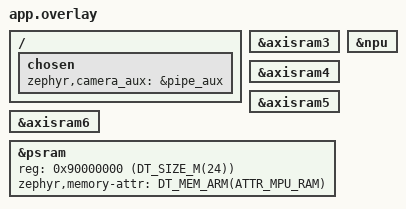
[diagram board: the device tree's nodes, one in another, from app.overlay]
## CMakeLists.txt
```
##############################################################################
# @file    CMakeLists.txt
# @author  GPM Application Team
#
##############################################################################
# @attention
#
# Copyright (c) 2025 STMicroelectronics.
# All rights reserved.
#
# This software is licensed under terms that can be found in the LICENSE file
# in the root directory of this software component.
# If no LICENSE file comes with this software, it is provided AS-IS.
#
##############################################################################

cmake_minimum_required(VERSION 3.20.0)

set(BOARD stm32n6570_dk)
set(SHIELD st_b_cams_imx_mb1854)

find_package(Zephyr REQUIRED HINTS $ENV{ZEPHYR_BASE})

project(app LANGUAGES C)

target_include_directories(app PRIVATE inc Model)
target_sources(app PRIVATE src/main.c src/model.c Model/network.c Model/stai_network.c src/zephyr_logo.c)

# lib_vision_models_pp
target_include_directories(app PRIVATE ../Lib/lib_vision_models_pp/lib_vision_models_pp/Inc
                           ../Lib/lib_vision_models_pp/Drivers/CMSIS/DSP/Include)

target_sources(app PRIVATE ../Lib/lib_vision_models_pp/lib_vision_models_pp/Src/vision_models_pp.c
                           ../Lib/lib_vision_models_pp/lib_vision_models_pp/Src/vision_models_pp_maxi_if32.c
                           ../Lib/lib_vision_models_pp/lib_vision_models_pp/Src/vision_models_pp_maxi_is8.c
                           ../Lib/lib_vision_models_pp/lib_vision_models_pp/Src/vision_models_pp_maxi_iu8.c
                           ../Lib/lib_vision_models_pp/lib_vision_models_pp/Src/od_pp_yolov2.c
                           ../Lib/lib_vision_models_pp/lib_vision_models_pp/Src/od_pp_yolov5.c
                           ../Lib/lib_vision_models_pp/lib_vision_models_pp/Src/od_pp_yolov8.c
                           ../Lib/lib_vision_models_pp/lib_vision_models_pp/Src/od_pp_st_yolox.c)

# AI_Runtime
target_compile_definitions(app PRIVATE LL_ATON_PLATFORM=LL_ATON_PLAT_STM32N6
                           LL_ATON_OSAL=LL_ATON_OSAL_ZEPHYR
                           LL_ATON_RT_MODE=LL_ATON_RT_ASYNC
                           LL_ATON_SW_FALLBACK
                           LL_ATON_DBG_BUFFER_INFO_EXCLUDED=1
                           APP_HAS_PARALLEL_NETWORKS=0)

target_include_directories(app PRIVATE ../Lib/AI_Runtime/Inc
                           ../Lib/AI_Runtime/Npu/ll_aton
                           ../Lib/AI_Runtime/Npu/Devices/STM32N6xx)

target_sources(app PRIVATE ../Lib/AI_Runtime/Npu/ll_aton/ll_aton.c
               ../Lib/AI_Runtime/Npu/ll_aton/ll_aton_osal_zephyr.c
               ../Lib/AI_Runtime/Npu/ll_aton/ll_aton_debug.c
               ../Lib/AI_Runtime/Npu/ll_aton/ll_aton_lib.c
               ../Lib/AI_Runtime/Npu/ll_aton/ll_aton_lib_sw_operators.c
               ../Lib/AI_Runtime/Npu/ll_aton/ll_aton_rt_main.c
               ../Lib/AI_Runtime/Npu/ll_aton/ll_aton_runtime.c
               ../Lib/AI_Runtime/Npu/ll_aton/ll_aton_cipher.c
               ../Lib/AI_Runtime/Npu/ll_aton/ll_aton_stai_internal.c
               ../Lib/AI_Runtime/Npu/ll_aton/ll_aton_util.c
               ../Lib/AI_Runtime/Npu/ll_aton/ll_sw_float.c
               ../Lib/AI_Runtime/Npu/ll_aton/ll_sw_integer.c
               ../Lib/AI_Runtime/Npu/ll_aton/ecloader.c
               ../Lib/AI_Runtime/Npu/Devices/STM32N6xx/npu_cache.c
               ../Lib/AI_Runtime/Npu/Devices/STM32N6xx/mcu_cache.c)

target_link_directories(app PUBLIC ../Lib/AI_Runtime/Lib/GCC/ARMCortexM55)

target_link_libraries(app PRIVATE :NetworkRuntime1100_CM55_GCC.a)
```

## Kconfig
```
##############################################################################
# @file    Kconfig
# @author  GPM Application Team
#
##############################################################################
# @attention
#
# Copyright (c) 2025 STMicroelectronics.
# All rights reserved.
#
# This software is licensed under terms that can be found in the LICENSE file
# in the root directory of this software component.
# If no LICENSE file comes with this software, it is provided AS-IS.
#
##############################################################################

mainmenu "Zephyr people detect"

menu "Application options"
config MY_APP
	bool "Enable app"
	default y
	select USE_STM32_HAL_RAMCFG
	select USE_STM32_HAL_CACHEAXI
	select FPU
	select CMSIS_DSP
	help
		enable application

endmenu

source "Kconfig.zephyr"
```

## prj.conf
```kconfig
# Copyright (c) 2025 STMicroelectronics
# All rights reserved.
#
# This software is licensed under terms that can be found in the LICENSE file
# in the root directory of this software component.
# If no LICENSE file comes with this software, it is provided AS-IS.

CONFIG_MY_APP=y
CONFIG_MAIN_STACK_SIZE=8192
# CONFIG_XIP is not set
CONFIG_USE_STM32_MW_ISP=y
CONFIG_DYNAMIC_INTERRUPTS=y
CONFIG_FLASH=y
CONFIG_HW_STACK_PROTECTION=y
CONFIG_LOG=y
CONFIG_ASSERT=y
CONFIG_LV_USE_CANVAS=y
CONFIG_LV_USE_THEME_DEFAULT=y
CONFIG_LVGL=y
CONFIG_LV_Z_MEM_POOL_SIZE=8192
# CONFIG_THREAD_MONITOR is not set
# CONFIG_THREAD_NAME is not set
CONFIG_DISPLAY=y
CONFIG_FLASH_STM32_NOR_MEMMAP=y
CONFIG_VIDEO=y
CONFIG_VIDEO_BUFFER_POOL_NUM_MAX=4
CONFIG_VIDEO_BUFFER_POOL_HEAP_SIZE=2575000
CONFIG_VIDEO_STM32_DCMIPP_SENSOR_WIDTH=2592
CONFIG_VIDEO_STM32_DCMIPP_SENSOR_HEIGHT=1944
CONFIG_VIDEO_STM32_DCMIPP_SENSOR_PIXEL_FORMAT="pRAA"
CONFIG_CPU_LOAD=y
# To be sure LOGGER can still ouput message move this one priority level above main thread
CONFIG_LOG_PROCESS_THREAD_CUSTOM_PRIORITY=y
CONFIG_LOG_PROCESS_THREAD_PRIORITY=13
CONFIG_LV_FONT_UNSCII_16=y
CONFIG_LV_Z_MEM_POOL_SIZE=12288
```

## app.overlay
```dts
/*
 * Copyright (c) 2025 STMicroelectronics.
 * All rights reserved.
 *
 * This software is licensed under terms that can be found in the LICENSE file
 * in the root directory of this software component.
 * If no LICENSE file comes with this software, it is provided AS-IS.
 */

/ {
	chosen {
		zephyr,camera_aux = &pipe_aux;
	};
};

// Turn on so called npu rams. They will used by NPU for model actvation buffers
&axisram3 {
	status = "okay";
};
&axisram4 {
	status = "okay";
};
&axisram5 {
	status = "okay";
};
&axisram6 {
	status = "okay";
};

// Turn on npu
&npu {
	status = "okay";
};

// Temporary patch that allows to turn on cache on psram
// Remove this when merge upstream
&psram {
	/* Let last 8 Mbytes for Model usage */
	reg = <0x90000000 (DT_SIZE_M(24))>;
	zephyr,memory-attr = <DT_MEM_ARM(ATTR_MPU_RAM)>;
};
```

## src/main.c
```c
/**
 ******************************************************************************
 * @file    main.c
 * @author  GPM Application Team
 *
 ******************************************************************************
 * @attention
 *
 * Copyright (c) 2025 STMicroelectronics.
 * All rights reserved.
 *
 * This software is licensed under terms that can be found in the LICENSE file
 * in the root directory of this software component.
 * If no LICENSE file comes with this software, it is provided AS-IS.
 *
 ******************************************************************************
 */

#include <zephyr/kernel.h>
#include <zephyr/drivers/video.h>
#include <zephyr/drivers/display.h>
#include <zephyr/sys/__assert.h>
#include <zephyr/sys/cpu_load.h>
#include <zephyr/logging/log.h>
#include <zephyr/sys/util.h>

#include <lvgl.h>

#include <stdarg.h>

#include "model.h"
#include "stai_network.h"

LOG_MODULE_REGISTER(main);

#define DISPLAY_WIDTH DT_PROP(DT_CHOSEN(zephyr_display), width)
#define DISPLAY_HEIGHT DT_PROP(DT_CHOSEN(zephyr_display), height)
#define DISPLAY_BPP 2

#define NN_WIDTH STAI_NETWORK_IN_1_WIDTH
#define NN_HEIGHT STAI_NETWORK_IN_1_HEIGHT
#define NN_BPP 3
#define NPU_BUFFER_POOL_ALIGN 32

/* Tune ui layout */
#define APP_DRAW_INF_TIME 0
#define APP_DRAW_INF_FPS 1
#define APP_DRAW_CPU_LOAD 0
#define APP_DRAW_LOGO 1

LV_IMAGE_DECLARE(zephyr_logo);

static struct k_thread nn_thread;
static K_THREAD_STACK_DEFINE(nn_thread_stack, 4096);

static int display_setup(const struct device *const display_dev)
{
	int ret;

	ret = display_set_pixel_format(display_dev, PIXEL_FORMAT_RGB_565);
	__ASSERT_NO_MSG(ret == 0);

	ret = display_blanking_off(display_dev);
	__ASSERT_NO_MSG(ret == 0);

	return 0;
}

static void print_text(lv_layer_t *layer, int x, int y, lv_text_align_t align, char *fmt, ...)
{
	lv_draw_label_dsc_t tdsc;
	char text_buffer[128];
	lv_area_t coords;
	va_list ap;

	va_start(ap, fmt);
	vsnprintf(text_buffer, sizeof(text_buffer), fmt, ap);

	/* shadow */
	lv_draw_label_dsc_init(&tdsc);
	tdsc.color = lv_color_make(16, 16, 16);
	tdsc.font = &lv_font_unscii_16;
	coords.x1 = x + 1;
	coords.y1 = y + 1;
	coords.x2 = DISPLAY_WIDTH;
	coords.y2 = DISPLAY_HEIGHT;
	tdsc.text = text_buffer;
	tdsc.text_local = 1;
	tdsc.align = align;
	lv_draw_label(layer, &tdsc, &coords);

	/* text */
	tdsc.color = lv_color_make(255, 255, 255);
	coords.x1 = x;
	coords.y1 = y;
	lv_draw_label(layer, &tdsc, &coords);
	va_end(ap);
}

static void decorate_canvas(lv_obj_t * canvas)
{
	int latest_inference_time = model_get_latest_inference_time();
	const lv_font_t *font = &lv_font_unscii_16;
	lv_draw_image_dsc_t idsc;
	lv_draw_rect_dsc_t rdsc;
	struct dbox boxes[10];
	lv_area_t coords;
	lv_layer_t layer;
	struct dbox *b;
	uint32_t ver;
	int load;
	int nb;
	int i;

	ver = sys_kernel_version_get();
	nb = model_get_boxes(boxes, ARRAY_SIZE(boxes));

	lv_canvas_init_layer(canvas, &layer);
	/* Draw banner */
	print_text(&layer, 0, 0, LV_TEXT_ALIGN_CENTER, "YoloX People Detection");
	print_text(&layer, 0, font->line_height, LV_TEXT_ALIGN_CENTER, "Powered by zephyr OS %d.%d.%d",
		   SYS_KERNEL_VER_MAJOR(ver), SYS_KERNEL_VER_MINOR(ver), SYS_KERNEL_VER_PATCHLEVEL(ver));

	/* Draw inference time */
	if (APP_DRAW_INF_TIME) {
		print_text(&layer, 0, DISPLAY_HEIGHT - font->line_height * 3, LV_TEXT_ALIGN_LEFT, "Inference %d ms",
			   latest_inference_time);
	}
	/* Draw inference fps */
	if (APP_DRAW_INF_FPS) {
		latest_inference_time = latest_inference_time ? latest_inference_time : 1;
		print_text(&layer, 0, DISPLAY_HEIGHT - font->line_height * 2, LV_TEXT_ALIGN_LEFT, "Fps       %d",
			   1000 / latest_inference_time);
	}
	/* Draw cpu load */
#ifdef CONFIG_CPU_LOAD
	if (APP_DRAW_CPU_LOAD) {
		load = cpu_load_get(1);
		print_text(&layer, 0, DISPLAY_HEIGHT - font->line_height * 1, LV_TEXT_ALIGN_LEFT, "cpu load  %d.%d%%",
			   load / 10, load % 10);
	}
#else
	(void)load;
#endif

	/* Draw logo */
	if (APP_DRAW_LOGO) {
		lv_draw_image_dsc_init(&idsc);
		idsc.src = &zephyr_logo;
		coords.x1 = DISPLAY_WIDTH - zephyr_logo.header.w - 10;
		coords.y1 = DISPLAY_HEIGHT - zephyr_logo.header.h - 10;
		coords.x2 = coords.x1 + zephyr_logo.header.w - 1;
		coords.y2 = coords.y1 + zephyr_logo.header.h - 1;
		lv_draw_image(&layer, &idsc, &coords);
	}

	/* Draw boxes */
	lv_draw_rect_dsc_init(&rdsc);
	rdsc.border_color = lv_palette_main(LV_PALETTE_GREEN);
	rdsc.border_width = 2;
	rdsc.radius = 10;
	rdsc.bg_opa = 0;
	for (i = 0; i < nb; i++) {
		b = &boxes[i];
		coords.x1 = b->x;
		coords.y1 = b->y;
		coords.x2 = b->x + b->w;
		coords.y2 = b->y + b->h;
		lv_draw_rect(&layer, &rdsc, &coords);
	}

	lv_canvas_finish_layer(canvas, &layer);
}

static int video_crop_setup(const struct device *const video_dev, uint32_t sensor_width, uint32_t sensor_height)
{
	const float ratioy = (float)sensor_height / DISPLAY_HEIGHT;
	const float ratiox = (float)sensor_width / DISPLAY_WIDTH;
	const float ratio = MIN(ratiox, ratioy);
	struct video_selection crop = {
		.type = VIDEO_BUF_TYPE_OUTPUT,
	};
	int ret;

	__ASSERT_NO_MSG(ratio >= 1);
	__ASSERT_NO_MSG(ratio < 64);

	crop.target = VIDEO_SEL_TGT_CROP;
	crop.rect.width = DISPLAY_WIDTH * ratio;
	crop.rect.height = DISPLAY_HEIGHT * ratio;
	crop.rect.left = (sensor_width - crop.rect.width + 1) /2;
	crop.rect.top = (sensor_height - crop.rect.height + 1) / 2;

	ret = video_set_selection(video_dev, &crop);
	__ASSERT_NO_MSG(ret == 0);

	return 0;
}

static int video_resize_setup(const struct device *const video_dev, uint32_t width, uint32_t height)
{
	struct video_selection comp = {
		.type = VIDEO_BUF_TYPE_OUTPUT,
	};
	int ret;

	comp.target = VIDEO_SEL_TGT_COMPOSE;
	comp.rect.left = 0;
	comp.rect.top = 0;
	comp.rect.width = width;
	comp.rect.height = height;

	ret = video_set_selection(video_dev, &comp);
	__ASSERT_NO_MSG(ret == 0);

	return 0;
}

static int video_alloc_and_queue_buffers(const struct device *const video_dev, size_t bsize, int align)
{
	struct video_buffer *buffers[2];
	int ret;
	int i;

	for (i = 0; i < ARRAY_SIZE(buffers); i++) {
		buffers[i] = video_buffer_aligned_alloc(bsize, align, K_FOREVER);
		__ASSERT_NO_MSG(buffers[i]);
		buffers[i]->type = VIDEO_BUF_TYPE_OUTPUT;
		ret = video_enqueue(video_dev, buffers[i]);
		__ASSERT_NO_MSG(ret == 0);
		LOG_INF("buffer %p(%p) queue to %s pipe", (void *)buffers[i], (void *)buffers[i]->buffer, video_dev->name);
	}

	return 0;
}

static int video_main_setup(const struct device *const video_dev, uint32_t sensor_width, uint32_t sensor_height)
{
	struct video_format fmt;
	size_t bsize;
	int ret;

	/* setup crop, compose and output */
	ret = video_crop_setup(video_dev, sensor_width, sensor_height);
	__ASSERT_NO_MSG(ret == 0);
	ret = video_resize_setup(video_dev, DISPLAY_WIDTH, DISPLAY_HEIGHT);
	__ASSERT_NO_MSG(ret == 0);
	fmt.pixelformat = VIDEO_FOURCC_FROM_STR("RGBP");
	fmt.width = DISPLAY_WIDTH;
	fmt.height = DISPLAY_HEIGHT;
	fmt.pitch = fmt.width * DISPLAY_BPP;
	ret = video_set_format(video_dev, &fmt);
	__ASSERT_NO_MSG(ret == 0);

	/* alloc buffers and queue them */
	bsize = fmt.pitch * fmt.height;
	ret = video_alloc_and_queue_buffers(video_dev, bsize, CONFIG_VIDEO_BUFFER_POOL_ALIGN);
	__ASSERT_NO_MSG(ret == 0);

	return 0;
}

static int video_aux_setup(const struct device *const video_dev, uint32_t sensor_width, uint32_t sensor_height)
{
	struct video_format fmt;
	size_t bsize;
	int ret;

	/* setup crop, compose and output */
	ret = video_crop_setup(video_dev, sensor_width, sensor_height);
	__ASSERT_NO_MSG(ret == 0);
	ret = video_resize_setup(video_dev, NN_WIDTH, NN_HEIGHT);
	__ASSERT_NO_MSG(ret == 0);
	fmt.pixelformat = VIDEO_FOURCC_FROM_STR("RGB3");
	fmt.width = NN_WIDTH;
	fmt.height = NN_HEIGHT;
	fmt.pitch = fmt.width * NN_BPP;
	ret = video_set_format(video_dev, &fmt);
	__ASSERT_NO_MSG(ret == 0);

	/* alloc buffers and queue them */
	bsize = fmt.pitch * fmt.height;
	ret = video_alloc_and_queue_buffers(video_dev, bsize, NPU_BUFFER_POOL_ALIGN);
	__ASSERT_NO_MSG(ret == 0);

	return 0;
}

static int video_setup(const struct device *const main_dev, const struct device *const aux_dev)
{
	struct video_format fmt;
	uint32_t sensor_height;
	uint32_t sensor_width;
	int ret;

	/* get default format to get sensor width / height */
	ret = video_get_format(main_dev, &fmt);
	__ASSERT_NO_MSG(ret == 0);
	sensor_height = fmt.height;
	sensor_width = fmt.width;

	ret = video_main_setup(main_dev, sensor_width, sensor_height);
	__ASSERT_NO_MSG(ret == 0);

	ret = video_aux_setup(aux_dev, sensor_width, sensor_height);
	__ASSERT_NO_MSG(ret == 0);

	return 0;
}

int main()
{
	const struct device *const camera_aux_dev = DEVICE_DT_GET(DT_CHOSEN(zephyr_camera_aux));
	const struct device *const display_dev = DEVICE_DT_GET(DT_CHOSEN(zephyr_display));
	const struct device *const video_dev = DEVICE_DT_GET(DT_CHOSEN(zephyr_camera));
	struct video_buffer *vbuf;
	lv_obj_t *canvas;
	k_tid_t nn_tid;
	int ret;

	__ASSERT_NO_MSG(device_is_ready(video_dev));
	__ASSERT_NO_MSG(device_is_ready(camera_aux_dev));
	__ASSERT_NO_MSG(device_is_ready(display_dev));

	/* move main thread priority to lowest one so we let others thread a chance to run */
	k_thread_priority_set(k_current_get(), K_LOWEST_APPLICATION_THREAD_PRIO);

	/* create thread for nn process */
	nn_tid = k_thread_create(&nn_thread, nn_thread_stack, K_THREAD_STACK_SIZEOF(nn_thread_stack), model_thread_ep,
				 (void *) camera_aux_dev, NULL, NULL, 0, 0, K_NO_WAIT);
	__ASSERT_NO_MSG(nn_tid);

	/* Configure display */
	ret = display_setup(display_dev);
	__ASSERT_NO_MSG(ret == 0);

	/* Configure video pipe */
	ret = video_setup(video_dev, camera_aux_dev);
	__ASSERT_NO_MSG(ret == 0);

	/* Start main pipe */
	LOG_INF("Starting main pipe");
	ret = video_stream_start(video_dev, VIDEO_BUF_TYPE_OUTPUT);
	__ASSERT_NO_MSG(ret == 0);

	LOG_INF("Starting aux pipe");
	ret = video_stream_start(camera_aux_dev, VIDEO_BUF_TYPE_OUTPUT);
	__ASSERT_NO_MSG(ret == 0);

	LOG_INF("STARTING");

	canvas = lv_canvas_create(lv_scr_act());
	while (1) {
		ret = video_dequeue(video_dev, &vbuf, K_FOREVER);
		__ASSERT_NO_MSG(ret == 0);

		lv_canvas_set_buffer(canvas, vbuf->buffer, DISPLAY_WIDTH, DISPLAY_HEIGHT, LV_COLOR_FORMAT_RGB565);
		decorate_canvas(canvas);
		lv_timer_handler();

		ret = video_enqueue(video_dev, vbuf);
		__ASSERT_NO_MSG(ret == 0);
	}

	return 0;
}
```

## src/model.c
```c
/**
 ******************************************************************************
 * @file    model.c
 * @author  GPM Application Team
 *
 ******************************************************************************
 * @attention
 *
 * Copyright (c) 2025 STMicroelectronics.
 * All rights reserved.
 *
 * This software is licensed under terms that can be found in the LICENSE file
 * in the root directory of this software component.
 * If no LICENSE file comes with this software, it is provided AS-IS.
 *
 ******************************************************************************
 */

#include "model.h"

#include <stdlib.h>

#include <zephyr/cache.h>
#include <zephyr/drivers/video.h>
#include <zephyr/logging/log.h>
#include <zephyr/mem_mgmt/mem_attr_heap.h>

#include "npu_cache.h"
#include "stai.h"
#include "stai_network.h"
#include "od_st_yolox_pp_if.h"

#define DISPLAY_WIDTH DT_PROP(DT_CHOSEN(zephyr_display), width)
#define DISPLAY_HEIGHT DT_PROP(DT_CHOSEN(zephyr_display), height)

/* post process conf */
 /* Tunable post process parameters */
#define AI_OD_ST_YOLOX_PP_IOU_THRESHOLD             (0.5)
#define AI_OD_ST_YOLOX_PP_CONF_THRESHOLD            (0.6)
#define AI_OD_ST_YOLOX_PP_MAX_BOXES_LIMIT           (10)
 /* Model related defines */
#define AI_OD_ST_YOLOX_PP_NB_CLASSES                (1)
#define AI_OD_ST_YOLOX_PP_L_GRID_WIDTH              (52)
#define AI_OD_ST_YOLOX_PP_L_GRID_HEIGHT             (52)
#define AI_OD_ST_YOLOX_PP_M_GRID_WIDTH              (26)
#define AI_OD_ST_YOLOX_PP_M_GRID_HEIGHT             (26)
#define AI_OD_ST_YOLOX_PP_S_GRID_WIDTH              (13)
#define AI_OD_ST_YOLOX_PP_S_GRID_HEIGHT             (13)
#define AI_OD_ST_YOLOX_PP_NB_ANCHORS                (3)
/* Anchor boxes */
static const float32_t AI_OD_ST_YOLOX_PP_L_ANCHORS[2 * AI_OD_ST_YOLOX_PP_NB_ANCHORS] = {26.000000, 26.000000, 3.640000, 13.000000, 11.960000, 36.40000};
static const float32_t AI_OD_ST_YOLOX_PP_M_ANCHORS[2 * AI_OD_ST_YOLOX_PP_NB_ANCHORS] = {13.000000, 13.000000, 1.820000,  6.500000,  5.980000, 18.20000};
static const float32_t AI_OD_ST_YOLOX_PP_S_ANCHORS[2 * AI_OD_ST_YOLOX_PP_NB_ANCHORS] = { 6.500000,  6.500000, 0.910000,  3.250000,  2.990000,  9.10000};


LOG_MODULE_REGISTER(model);

/* Model instance buffer */
static uint8_t network_ctx[STAI_NETWORK_CONTEXT_SIZE] __attribute__ ((aligned (32)));

/* Post process */
static stai_network_info *current_info;
static size_t output_order_index[3];

/* latest detections and associate mutex */
static od_pp_outBuffer_t pp_detections_buffer[AI_OD_ST_YOLOX_PP_NB_ANCHORS *
					      MAX(AI_OD_ST_YOLOX_PP_MAX_BOXES_LIMIT,
						  AI_OD_ST_YOLOX_PP_L_GRID_WIDTH * AI_OD_ST_YOLOX_PP_L_GRID_HEIGHT +
						  AI_OD_ST_YOLOX_PP_M_GRID_WIDTH * AI_OD_ST_YOLOX_PP_M_GRID_HEIGHT +
						  AI_OD_ST_YOLOX_PP_S_GRID_WIDTH * AI_OD_ST_YOLOX_PP_S_GRID_HEIGHT)];
static od_pp_outBuffer_t detections[AI_OD_ST_YOLOX_PP_MAX_BOXES_LIMIT];
static int detections_nb = -1;
static struct k_mutex boxes_lock;

static int latest_inference_time = 0;

static void Run_Inference(stai_network *network_instance)
{
	stai_return_code ret;

	do {
		ret = stai_network_run(network_instance, STAI_MODE_ASYNC);
		if (ret == STAI_RUNNING_WFE)
			LL_ATON_OSAL_WFE();
	} while (ret == STAI_RUNNING_WFE || ret == STAI_RUNNING_NO_WFE);

	ret = stai_ext_network_new_inference(network_instance);
	assert(ret == STAI_SUCCESS);
}


static void NPUCache_config()
{
	npu_cache_enable();
}

static void model_npu_init()
{
	NPUCache_config();

	LOG_INF("Npu subsystem ready");
}

static int clamp_point(int *x, int *y)
{
	int xi = *x;
	int yi = *y;

	if (*x < 0)
		*x = 0;
	if (*y < 0)
		*y = 0;
	if (*x >= DISPLAY_WIDTH)
		*x = DISPLAY_WIDTH - 1;
	if (*y >= DISPLAY_HEIGHT)
		*y = DISPLAY_HEIGHT - 1;

	return (xi != *x) || (yi != *y);
}

static void convert_length(float32_t wi, float32_t hi, int *wo, int *ho)
{
	*wo = (int) (DISPLAY_WIDTH * wi);
	*ho = (int) (DISPLAY_HEIGHT * hi);
}

static void convert_point(float32_t xi, float32_t yi, int *xo, int *yo)
{
	*xo = (int) (DISPLAY_WIDTH * xi);
	*yo = (int) (DISPLAY_HEIGHT * yi);
}

static void model_detection_to_box(od_pp_outBuffer_t *d, struct dbox *b)
{
	int xc, yc;
	int x0, y0;
	int x1, y1;
	int w, h;

	convert_point(d->x_center, d->y_center, &xc, &yc);
	convert_length(d->width, d->height, &w, &h);
	x0 = xc - (w + 1) / 2;
	y0 = yc - (h + 1) / 2;
	x1 = xc + (w + 1) / 2;
	y1 = yc + (h + 1) / 2;
	clamp_point(&x0, &y0);
	clamp_point(&x1, &y1);
	w = x1 - x0 + 1;
	h = y1 - y0 + 1;

	b->x = x0;
	b->y = y0;
	b->w = w;
	b->h = h;
}

static int model_pp_compare_order_by_ascending_order(const void *el1, const void *el2)
{
  stai_network_info *info = current_info;
  size_t *idx1 = (size_t *) el1;
  size_t *idx2 = (size_t *) el2;

  return info->outputs[*idx1].size_bytes - info->outputs[*idx2].size_bytes;
}

static void model_pp_order_outputs(size_t *outputs_idx, size_t size, stai_network_info *info)
{
  for (size_t i = 0; i < size; i++) {
    outputs_idx[i] = i;
  }

  current_info = info;
  qsort(outputs_idx, size, sizeof(size_t), model_pp_compare_order_by_ascending_order);
  current_info = NULL;
}

static void model_pp_init(od_st_yolox_pp_static_param_t *params, stai_network_info *info)
{
	int ret;

	/* Model output orders may change. So order them by size */
	model_pp_order_outputs(output_order_index, 3, info);

	params->nb_classes = AI_OD_ST_YOLOX_PP_NB_CLASSES;
	params->nb_anchors = AI_OD_ST_YOLOX_PP_NB_ANCHORS;
	params->grid_width_S = AI_OD_ST_YOLOX_PP_S_GRID_WIDTH;
	params->grid_height_S = AI_OD_ST_YOLOX_PP_S_GRID_HEIGHT;
	params->pAnchors_S = AI_OD_ST_YOLOX_PP_S_ANCHORS;
	params->grid_width_M = AI_OD_ST_YOLOX_PP_M_GRID_WIDTH;
	params->grid_height_M = AI_OD_ST_YOLOX_PP_M_GRID_HEIGHT;
	params->pAnchors_M = AI_OD_ST_YOLOX_PP_M_ANCHORS;
	params->grid_width_L = AI_OD_ST_YOLOX_PP_L_GRID_WIDTH;
	params->grid_height_L = AI_OD_ST_YOLOX_PP_L_GRID_HEIGHT;
	params->pAnchors_L = AI_OD_ST_YOLOX_PP_L_ANCHORS;
	params->max_boxes_limit = AI_OD_ST_YOLOX_PP_MAX_BOXES_LIMIT;
	params->conf_threshold = AI_OD_ST_YOLOX_PP_CONF_THRESHOLD;
	params->iou_threshold = AI_OD_ST_YOLOX_PP_IOU_THRESHOLD;

	ret = od_st_yolox_pp_reset(params);
	__ASSERT_NO_MSG(ret == 0);
}

static void model_pp_run(stai_ptr nn_outputs[3], od_pp_out_t *pp_out, od_st_yolox_pp_static_param_t *params)
{
	od_st_yolox_pp_in_t pp_input;
	int ret;

	pp_input.pRaw_detections_S = (float32_t *) nn_outputs[output_order_index[0]];
	pp_input.pRaw_detections_M = (float32_t *) nn_outputs[output_order_index[1]];
	pp_input.pRaw_detections_L = (float32_t *) nn_outputs[output_order_index[2]];
	pp_out->pOutBuff = pp_detections_buffer;
	params->nb_detect = 0;
	ret = od_st_yolox_pp_process(&pp_input, pp_out, params);
	__ASSERT_NO_MSG(ret == 0);
}

void model_thread_ep(void *arg1, void *arg2, void *arg3)
{
	const struct device *const camera_aux_dev = arg1;
	stai_size nn_out_len[STAI_NETWORK_OUT_NUM];
	stai_ptr outputs[STAI_NETWORK_OUT_NUM];
	od_st_yolox_pp_static_param_t pp_params;
	struct video_buffer *vbuf;
	stai_network_info info;
	od_pp_out_t pp_output;
	stai_size output_nb;
	stai_ptr inputs[1];
	uint32_t tick;
	int ret;
	int i;

	ret = k_mutex_init(&boxes_lock);
	__ASSERT_NO_MSG(ret == 0);
	detections_nb = 0;

	model_npu_init();

	/* initialize runtime */
	ret = stai_runtime_init();
	__ASSERT_NO_MSG(ret == STAI_SUCCESS);
	/* init model instance */
	ret = stai_network_init(network_ctx);
	__ASSERT_NO_MSG(ret == STAI_SUCCESS);

	/* setup buffers size */
	ret = stai_network_get_info(network_ctx, &info);
	__ASSERT_NO_MSG(ret == STAI_SUCCESS);
	__ASSERT_NO_MSG(info.n_inputs == 1);
	__ASSERT_NO_MSG(info.n_outputs == 3);
	ret = stai_network_get_outputs(network_ctx, outputs, &output_nb);
	__ASSERT_NO_MSG(ret == STAI_SUCCESS);
	for (i = 0; i < output_nb; i++)
		nn_out_len[i] = info.outputs[i].size_bytes;

	/* pp init */
	model_pp_init(&pp_params, &info);

	while (1) {
		ret = video_dequeue(camera_aux_dev, &vbuf, K_FOREVER);
		__ASSERT_NO_MSG(ret == 0);

		/* run inference */
		 /* setup input buffer. No need cache ops since full hw path DCMIPP -> NPU */
		inputs[0] = vbuf->buffer;
		ret = stai_network_set_inputs(network_ctx, inputs, ARRAY_SIZE(inputs));
		__ASSERT_NO_MSG(ret == STAI_SUCCESS);
		 /* setup output. Invalidate ouputs so post-process access latest inference result */
		for (i = 0; i < output_nb; i++) {
			ret = sys_cache_data_invd_range(outputs[i], nn_out_len[i]);
			__ASSERT_NO_MSG(ret == 0);
		}
		 /* let's go */
		tick = HAL_GetTick();
		Run_Inference(network_ctx);
		tick = HAL_GetTick() - tick;
		latest_inference_time = tick;

		ret = video_enqueue(camera_aux_dev, vbuf);
		__ASSERT_NO_MSG(ret == 0);

		/* post process */
		model_pp_run(outputs, &pp_output, &pp_params);

		/* boxes state */
		ret = k_mutex_lock(&boxes_lock, K_FOREVER);
		__ASSERT_NO_MSG(ret == 0);

		detections_nb = pp_output.nb_detect;
		for (i = 0; i < pp_output.nb_detect; i++)
			detections[i] = pp_output.pOutBuff[i];

		ret = k_mutex_unlock(&boxes_lock);
		__ASSERT_NO_MSG(ret == 0);
	}
}

int model_get_boxes(struct dbox *boxes, int boxes_nb)
{
	int nb = 0;
	int ret;
	int i;

	/* not yet init */
	if (detections_nb < 0)
		return 0;

	ret = k_mutex_lock(&boxes_lock, K_FOREVER);
	__ASSERT_NO_MSG(ret == 0);

	nb = MIN(boxes_nb, detections_nb);
	for (i = 0; i < nb; i++)
		model_detection_to_box(&detections[i], &boxes[i]);

	ret = k_mutex_unlock(&boxes_lock);
	__ASSERT_NO_MSG(ret == 0);

	return nb;
}

int model_get_latest_inference_time()
{
	return latest_inference_time;
}
```

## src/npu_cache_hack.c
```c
/**
 ******************************************************************************
 * @file    npu_cache_hack.c
 * @author  GPM Application Team
 *
 ******************************************************************************
 * @attention
 *
 * Copyright (c) 2026 STMicroelectronics.
 * All rights reserved.
 *
 * This software is licensed under terms that can be found in the LICENSE file
 * in the root directory of this software component.
 * If no LICENSE file comes with this software, it is provided AS-IS.
 *
 ******************************************************************************
 */

#include "stm32n6xx_hal.h"

/* 3.0.0 version of ../../Lib/AI_Runtime/Npu/Devices/STM32N6xx/npu_cache.c will not compile in zephyr due bad zephyr
 * hal order.
 * This file add stm32n6xx_hal.h so we include hal tpes before compiling original npu_cache.c.
 */

#include "../../Lib/AI_Runtime/Npu/Devices/STM32N6xx/npu_cache.c"
```
